# htmr_reva_me55 register map
Registers are access not given, no defined reset value unless marked. A register's access mark holds for its fields unless they carry their own. Offsets are from the block's base; lines under a group give offsets from that group; [hi:lo] are bit positions; {n}, {i} and the like mark numbered series; 'fields as' and 'values as' point back to an identical list; <NAME> marks a mode.

## Memory map
0x4001B000 HTMR size 0xFFF — High Speed Timer Module.

## Interrupts
93 HTimer (HTMR) — HTimer interrupt.

## HTMR — High Speed Timer Module.
Base 0x4001B000
0x00 LNICNT — HTimer Long-Interval Counter. This register contains the 32 most significant bits of the counter.
  [31:0] CNT — HTimer Long Interval Counter.
0x04 SHICNT — HTimer Short Interval Counter. This counter ticks every t_htclk (16.48uS). HTIMER_SEC is incremented when this register rolls over from 0xFF to 0x00.
  [7:0] CNT — HTimer Short Interval Counter.
0x08 LNIALM — HTimer Long Interval Alarm Value Register.
  [19:0] ALM — HTimer Long Interval Alarm. An Alarm is triggered when this value matches HTIMER_SEC[19:0]
0x0C SHIALM — HTimer Short Interval Alarm Value Register.
  [31:0] ALM — This register contains the reload value for the short interval alarm.
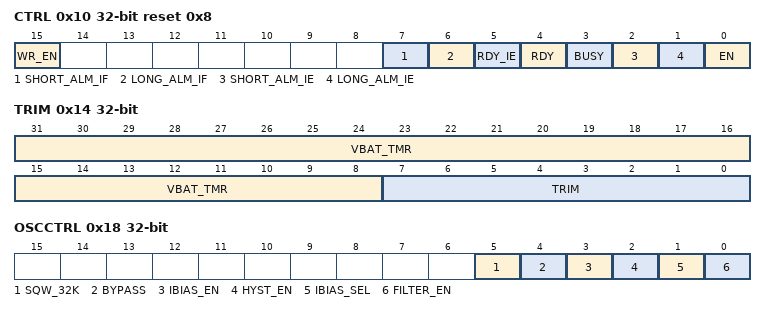
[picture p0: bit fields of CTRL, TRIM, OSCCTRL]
0x10 CTRL reset 0x8 — HTimer Control Register.
  [15] WR_EN — Write Enable. This register bit serves as a protection mechanism against unintentional writes to critical HTimer bits.
    0=dis (Not active.); 1=en
  [7] SHORT_ALM_IF ro — Short Interval Alarm Interrupt Flag. This alarm is qualified as wake-up source to the processor.
    0=inactive (Not active.); 1=Pending (Active.)
  [6] LONG_ALM_IF ro — Long Interval Alarm Interrupt Flag. This alarm is qualified as wake-up source to the processor.
    0=inactive (Not active.); 1=pending (Active.)
  [5] RDY_IE — HTimer Ready Interrupt Enable.
    0=dis (Disable.); 1=en (Enable.)
  [4] RDY — HTimer Ready. This bit is set to 1 by hardware when the HTimer count registers update. It can be cleared to 0 by software at any time. It will also be cleared to 0 by hardware just prior to an update of the HTimer count register.
    0=busy (Register has not updated.); 1=ready
  [3] BUSY ro — HTimer Busy. This bit is set to 1 by hardware when changes to HTimer registers required a synchronized version of the register to be in place. This bit is automatically cleared by hardware.
    0=idle; 1=busy
  [2] SHORT_ALM_IE — Short Interval Alarm Interrupt Enable. Change to this bit is effective only after BUSY is cleared from 1 to 0.
    0=dis (Disable.); 1=en (Enable.)
  [1] LONG_ALM_IE — Long Interval Alarm Interrupt Enable. Change to this bit is effective only after BUSY is cleared from 1 to 0.
    0=dis (Disable.); 1=en (Enable.)
  [0] EN — HTimer Enable. This bit enables the Real Time Clock. This bit can only be written when WE=1 and BUSY =0. Change to this bit is effective only after BUSY is cleared from 1 to 0.
    0=dis (Disable.); 1=en (Enable.)
0x14 TRIM — HTimer Trim Register.
  [31:8] VBAT_TMR — VBAT Timer Value. When HTimer is running off of VBAT, this field is incremented every 32 seconds.
  [7:0] TRIM — HTimer Trim. This register contains the 2's complement value that specifies the trim resolution. Each increment or decrement of the bit adds or subtracts 1ppm at each 4KHz clock value, with a maximum correction of +/- 127ppm.
0x18 OSCCTRL — HTimer Oscillator Control Register.
  [5] SQW_32K — HTimer 32kHz Square Wave Output
    0=dis (Disable.); 1=en (Enable.)
  [4] BYPASS — HTimer Crystal Bypass
    0=dis (Disable.); 1=en (Enable.)
  [3] IBIAS_EN — HTimer IBIAS Enable.
  [2] HYST_EN — HTimer Hysteresis Enable.
  [1] IBIAS_SEL — IBIAS Select.
    0=2x; 1=4x
  [0] FILTER_EN — Enable Filter.
